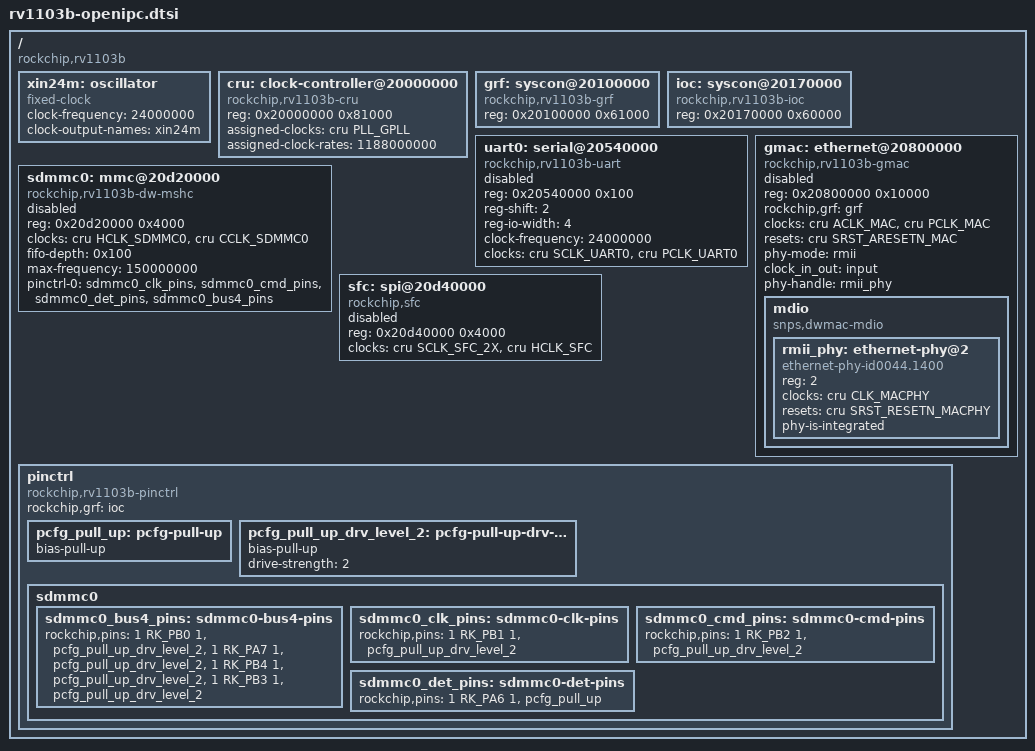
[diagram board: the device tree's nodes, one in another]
// SPDX-License-Identifier: (GPL-2.0+ OR MIT)
/*
 * RV1103B / RV1106B as OpenIPC's U-Boot sees it: the CRU and GRF, UART0,
 * the FSPI (the SFC by another name) with the boot flash, the Ethernet MAC
 * with the SoC's own 10/100 PHY, and the SD slot with its pins. Addresses,
 * clocks, resets and pins are the vendor SDK's (rockchip-linux/u-boot
 * next-dev, arch/arm/dts/rv1103b.dtsi and rv1103b-pinctrl.dtsi).
 */

#include <dt-bindings/clock/rockchip,rv1103b-cru.h>
#include <dt-bindings/pinctrl/rockchip.h>

/ {
	#address-cells = <1>;
	#size-cells = <1>;

	compatible = "rockchip,rv1103b";

	xin24m: oscillator {
		compatible = "fixed-clock";
		clock-frequency = <24000000>;
		clock-output-names = "xin24m";
		#clock-cells = <0>;
	};

	cru: clock-controller@20000000 {
		compatible = "rockchip,rv1103b-cru";
		reg = <0x20000000 0x81000>;
		#clock-cells = <1>;
		#reset-cells = <1>;

		/*
		 * The vendor tree also assigns CLK_GPLL_DIV12 (100 MHz), which
		 * the vendor clock driver has no code for: mainline would fail
		 * every device on this node with it. The kernel sets it.
		 */
		assigned-clocks = <&cru PLL_GPLL>;
		assigned-clock-rates = <1188000000>;
	};

	/* VEPU, NPU, VI, CPU, DDR, SYS and PMU GRF, one block apart each */
	grf: syscon@20100000 {
		compatible = "rockchip,rv1103b-grf", "syscon", "simple-mfd";
		reg = <0x20100000 0x61000>;
	};

	ioc: syscon@20170000 {
		compatible = "rockchip,rv1103b-ioc", "syscon";
		reg = <0x20170000 0x60000>;
	};

	/* The console; the mask ROM and the DDR blob set its pins (M0) */
	uart0: serial@20540000 {
		compatible = "rockchip,rv1103b-uart", "snps,dw-apb-uart";
		reg = <0x20540000 0x100>;
		reg-shift = <2>;
		reg-io-width = <4>;
		clock-frequency = <24000000>;
		clocks = <&cru SCLK_UART0>, <&cru PCLK_UART0>;
		clock-names = "baudclk", "apb_pclk";
		status = "disabled";
	};

	gmac: ethernet@20800000 {
		compatible = "rockchip,rv1103b-gmac", "snps,dwmac-4.20a";
		reg = <0x20800000 0x10000>;
		rockchip,grf = <&grf>;
		clocks = <&cru ACLK_MAC>, <&cru PCLK_MAC>;
		clock-names = "aclk_mac", "pclk_mac";
		resets = <&cru SRST_ARESETN_MAC>;
		reset-names = "stmmaceth";
		phy-mode = "rmii";
		clock_in_out = "input";
		phy-handle = <&rmii_phy>;
		status = "disabled";

		mdio: mdio {
			compatible = "snps,dwmac-mdio";
			#address-cells = <0x1>;
			#size-cells = <0x0>;

			rmii_phy: ethernet-phy@2 {
				compatible = "ethernet-phy-id0044.1400",
					     "ethernet-phy-ieee802.3-c22";
				reg = <2>;
				clocks = <&cru CLK_MACPHY>;
				resets = <&cru SRST_RESETN_MACPHY>;
				phy-is-integrated;
			};
		};
	};

	sdmmc0: mmc@20d20000 {
		compatible = "rockchip,rv1103b-dw-mshc", "rockchip,rk3288-dw-mshc";
		reg = <0x20d20000 0x4000>;
		clocks = <&cru HCLK_SDMMC0>, <&cru CCLK_SDMMC0>;
		clock-names = "biu", "ciu";
		fifo-depth = <0x100>;
		max-frequency = <150000000>;
		pinctrl-names = "default";
		pinctrl-0 = <&sdmmc0_clk_pins &sdmmc0_cmd_pins &sdmmc0_det_pins
			     &sdmmc0_bus4_pins>;
		status = "disabled";
	};

	sfc: spi@20d40000 {
		compatible = "rockchip,sfc";
		reg = <0x20d40000 0x4000>;
		clocks = <&cru SCLK_SFC_2X>, <&cru HCLK_SFC>;
		clock-names = "clk_sfc", "hclk_sfc";
		#address-cells = <1>;
		#size-cells = <0>;
		status = "disabled";
	};

	pinctrl: pinctrl {
		compatible = "rockchip,rv1103b-pinctrl";
		rockchip,grf = <&ioc>;
		#address-cells = <1>;
		#size-cells = <1>;
		ranges;

		pcfg_pull_up: pcfg-pull-up {
			bias-pull-up;
		};

		pcfg_pull_up_drv_level_2: pcfg-pull-up-drv-level-2 {
			bias-pull-up;
			drive-strength = <2>;
		};

		sdmmc0 {
			sdmmc0_bus4_pins: sdmmc0-bus4-pins {
				rockchip,pins =
					<1 RK_PB0 1 &pcfg_pull_up_drv_level_2>,
					<1 RK_PA7 1 &pcfg_pull_up_drv_level_2>,
					<1 RK_PB4 1 &pcfg_pull_up_drv_level_2>,
					<1 RK_PB3 1 &pcfg_pull_up_drv_level_2>;
			};

			sdmmc0_clk_pins: sdmmc0-clk-pins {
				rockchip,pins =
					<1 RK_PB1 1 &pcfg_pull_up_drv_level_2>;
			};

			sdmmc0_cmd_pins: sdmmc0-cmd-pins {
				rockchip,pins =
					<1 RK_PB2 1 &pcfg_pull_up_drv_level_2>;
			};

			sdmmc0_det_pins: sdmmc0-det-pins {
				rockchip,pins =
					<1 RK_PA6 1 &pcfg_pull_up>;
			};
		};
	};
};
